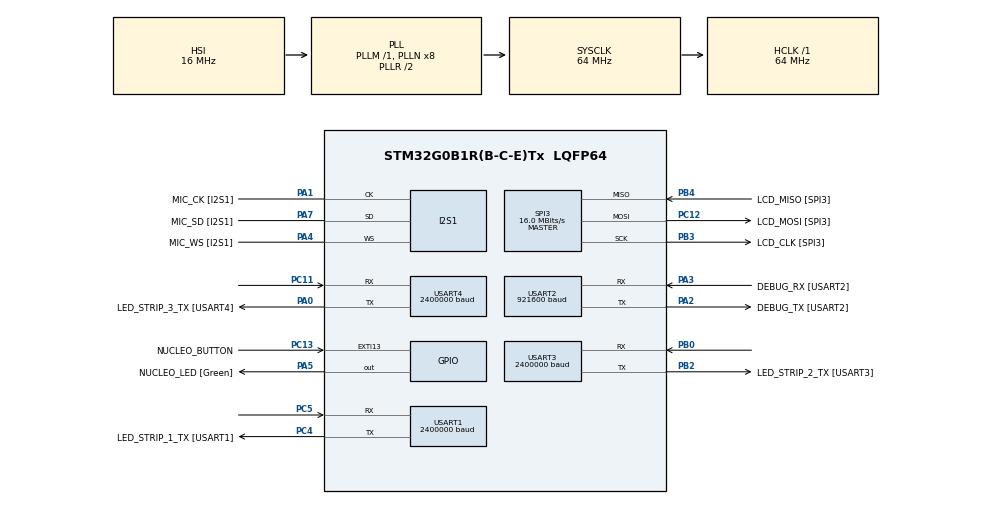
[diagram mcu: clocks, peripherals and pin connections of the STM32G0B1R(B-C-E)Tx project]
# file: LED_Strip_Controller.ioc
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Dma.Request0=USART1_TX
Dma.Request1=USART3_TX
Dma.Request2=USART4_TX
Dma.USART1_TX.0.Direction=DMA_MEMORY_TO_PERIPH
Dma.USART1_TX.0.EventEnable=DISABLE
Dma.USART1_TX.0.Instance=DMA1_Channel1
Dma.USART1_TX.0.MemDataAlignment=DMA_MDATAALIGN_BYTE
Dma.USART1_TX.0.MemInc=DMA_MINC_ENABLE
Dma.USART1_TX.0.Mode=DMA_NORMAL
Dma.USART1_TX.0.PeriphDataAlignment=DMA_PDATAALIGN_BYTE
Dma.USART1_TX.0.PeriphInc=DMA_PINC_DISABLE
Dma.USART1_TX.0.Polarity=HAL_DMAMUX_REQ_GEN_RISING
Dma.USART1_TX.0.Priority=DMA_PRIORITY_LOW
Dma.USART1_TX.0.RequestNumber=1
Dma.USART1_TX.0.SignalID=NONE
Dma.USART1_TX.0.SyncEnable=DISABLE
Dma.USART1_TX.0.SyncPolarity=HAL_DMAMUX_SYNC_NO_EVENT
Dma.USART1_TX.0.SyncRequestNumber=1
Dma.USART1_TX.0.SyncSignalID=NONE
Dma.USART3_TX.1.Direction=DMA_MEMORY_TO_PERIPH
Dma.USART3_TX.1.EventEnable=DISABLE
Dma.USART3_TX.1.Instance=DMA1_Channel2
Dma.USART3_TX.1.MemDataAlignment=DMA_MDATAALIGN_BYTE
Dma.USART3_TX.1.MemInc=DMA_MINC_ENABLE
Dma.USART3_TX.1.Mode=DMA_NORMAL
Dma.USART3_TX.1.PeriphDataAlignment=DMA_PDATAALIGN_BYTE
Dma.USART3_TX.1.PeriphInc=DMA_PINC_DISABLE
Dma.USART3_TX.1.Polarity=HAL_DMAMUX_REQ_GEN_RISING
Dma.USART3_TX.1.Priority=DMA_PRIORITY_LOW
Dma.USART3_TX.1.RequestNumber=1
Dma.USART3_TX.1.SignalID=NONE
Dma.USART3_TX.1.SyncEnable=DISABLE
Dma.USART3_TX.1.SyncPolarity=HAL_DMAMUX_SYNC_NO_EVENT
Dma.USART3_TX.1.SyncRequestNumber=1
Dma.USART3_TX.1.SyncSignalID=NONE
Dma.USART4_TX.2.Direction=DMA_MEMORY_TO_PERIPH
Dma.USART4_TX.2.EventEnable=DISABLE
Dma.USART4_TX.2.Instance=DMA1_Channel3
Dma.USART4_TX.2.MemDataAlignment=DMA_MDATAALIGN_BYTE
Dma.USART4_TX.2.MemInc=DMA_MINC_ENABLE
Dma.USART4_TX.2.Mode=DMA_NORMAL
Dma.USART4_TX.2.PeriphDataAlignment=DMA_PDATAALIGN_BYTE
Dma.USART4_TX.2.PeriphInc=DMA_PINC_DISABLE
Dma.USART4_TX.2.Polarity=HAL_DMAMUX_REQ_GEN_RISING
Dma.USART4_TX.2.Priority=DMA_PRIORITY_LOW
Dma.USART4_TX.2.RequestNumber=1
Dma.USART4_TX.2.SignalID=NONE
Dma.USART4_TX.2.SyncEnable=DISABLE
Dma.USART4_TX.2.SyncPolarity=HAL_DMAMUX_SYNC_NO_EVENT
Dma.USART4_TX.2.SyncRequestNumber=1
Dma.USART4_TX.2.SyncSignalID=NONE
I2S1.ErrorAudioFreq=0.0 %
I2S1.FullDuplexMode=I2S_FULLDUPLEXMODE_DISABLE
I2S1.Instance=SPI$Index
I2S1.RealAudioFreq=8.0 KHz
I2S1.VirtualMode=I2S_MODE_MASTER
Mcu.Family=STM32G0
Mcu.Name=STM32G0B1R(B-C-E)Tx
Mcu.Package=LQFP64
NVIC.DMA1_Channel1_IRQn=true\:1\:0\:true\:false\:true\:false\:true\:true
NVIC.DMA1_Channel2_3_IRQn=true\:1\:0\:true\:false\:true\:false\:true\:true
NVIC.USART1_IRQn=true\:0\:0\:false\:false\:true\:true\:true\:true
NVIC.USART3_4_5_6_LPUART1_IRQn=true\:0\:0\:false\:false\:true\:true\:true\:true
PA0.GPIO_Label=LED_STRIP_3_TX [USART4]
PA0.Mode=Asynchronous
PA0.Signal=USART4_TX
PA1.GPIO_Label=MIC_CK [I2S1]
PA1.Mode=Half_Duplex_Master
PA1.Signal=I2S1_CK
PA13.GPIO_Label=SWDATA [STLink]
PA13.Mode=Serial_Wire
PA13.Signal=SYS_SWDIO
PA14-BOOT0.GPIO_Label=SWCLK [STLink]
PA14-BOOT0.Mode=Serial_Wire
PA14-BOOT0.Signal=SYS_SWCLK
PA2.GPIO_Label=DEBUG_TX [USART2]
PA2.Mode=Asynchronous
PA2.Signal=USART2_TX
PA3.GPIO_Label=DEBUG_RX [USART2]
PA3.Mode=Asynchronous
PA3.Signal=USART2_RX
PA4.GPIO_Label=MIC_WS [I2S1]
PA4.Mode=Half_Duplex_Master
PA4.Signal=I2S1_WS
PA5.GPIO_Label=NUCLEO_LED [Green]
PA5.GPIO_Speed=GPIO_SPEED_FREQ_HIGH
PA5.Signal=GPIO_Output
PA7.GPIO_Label=MIC_SD [I2S1]
PA7.Mode=Half_Duplex_Master
PA7.Signal=I2S1_SD
PB0.Mode=Asynchronous
PB0.Signal=USART3_RX
PB2.GPIO_Label=LED_STRIP_2_TX [USART3]
PB2.Mode=Asynchronous
PB2.Signal=USART3_TX
PB3.GPIO_Label=LCD_CLK [SPI3]
PB3.Mode=Full_Duplex_Master
PB3.Signal=SPI3_SCK
PB4.GPIO_Label=LCD_MISO [SPI3]
PB4.Mode=Full_Duplex_Master
PB4.Signal=SPI3_MISO
PC11.Mode=Asynchronous
PC11.Signal=USART4_RX
PC12.GPIO_Label=LCD_MOSI [SPI3]
PC12.Mode=Full_Duplex_Master
PC12.Signal=SPI3_MOSI
PC13.GPIO_Label=NUCLEO_BUTTON
PC13.Signal=GPXTI13
PC14-OSC32_IN\ (PC14).Mode=LSE-External-Oscillator
PC14-OSC32_IN\ (PC14).Signal=RCC_OSC32_IN
PC15-OSC32_OUT\ (PC15).Mode=LSE-External-Oscillator
PC15-OSC32_OUT\ (PC15).Signal=RCC_OSC32_OUT
PC4.GPIO_Label=LED_STRIP_1_TX [USART1]
PC4.Mode=Asynchronous
PC4.Signal=USART1_TX
PC5.Mode=Asynchronous
PC5.Signal=USART1_RX
PF0-OSC_IN\ (PF0).GPIO_Label=MCO[Reserved]
PF0-OSC_IN\ (PF0).Mode=HSE-External-Clock-Source
PF0-OSC_IN\ (PF0).Signal=RCC_OSC_IN
ProjectManager.HeapSize=0x4000
ProjectManager.StackSize=0x1000
ProjectManager.TargetToolchain=STM32CubeIDE
RCC.ADCFreq_Value=64000000
RCC.AHBFreq_Value=64000000
RCC.CortexFreq_Value=64000000
RCC.EXTERNAL_CLOCK_VALUE=12288000
RCC.HCLKFreq_Value=64000000
RCC.HSE_VALUE=8000000
RCC.HSI48_VALUE=48000000
RCC.HSI_VALUE=16000000
RCC.SYSCLKFreq_VALUE=64000000
RCC.SYSCLKSource=RCC_SYSCLKSOURCE_PLLCLK
RCC.USBFreq_Value=48000000
RCC.VCOOutputFreq_Value=128000000
RTC.Format=RTC_FORMAT_BIN
SPI3.BaudRatePrescaler=SPI_BAUDRATEPRESCALER_4
SPI3.CLKPolarity=SPI_POLARITY_HIGH
SPI3.CalculateBaudRate=16.0 MBits/s
SPI3.DataSize=SPI_DATASIZE_8BIT
SPI3.Direction=SPI_DIRECTION_2LINES
SPI3.Mode=SPI_MODE_MASTER
SPI3.VirtualType=VM_MASTER
TIM6.Period=1000
TIM6.Prescaler=63
TIM7.Prescaler=63
USART1.BaudRate=2400000
USART1.FIFOMode=FIFOMODE_ENABLE
USART1.Mode=MODE_TX
USART1.OneBitSampling=UART_ONE_BIT_SAMPLE_ENABLE
USART1.OverSampling=UART_OVERSAMPLING_8
USART1.RXFIFOThreshold=RXFIFO_THRESHOLD_HALFFULL
USART1.TXFIFOThreshold=TXFIFO_THRESHOLD_HALFFULL
USART1.TxPinLevelInvertParam=ADVFEATURE_TXINV_ENABLE
USART1.VirtualMode-Asynchronous=VM_ASYNC
USART1.WordLength=WORDLENGTH_7B
USART2.BaudRate=921600
USART2.Mode=MODE_TX_RX
USART2.RXFIFOThreshold=RXFIFO_THRESHOLD_HALFFULL
USART2.TXFIFOThreshold=TXFIFO_THRESHOLD_HALFFULL
USART2.TxPinLevelInvertParam=ADVFEATURE_TXINV_DISABLE
USART2.VirtualMode-Asynchronous=VM_ASYNC
USART3.BaudRate=2400000
USART3.FIFOMode=FIFOMODE_ENABLE
USART3.Mode=MODE_TX
USART3.OneBitSampling=UART_ONE_BIT_SAMPLE_ENABLE
USART3.OverSampling=UART_OVERSAMPLING_8
USART3.RXFIFOThreshold=RXFIFO_THRESHOLD_HALFFULL
USART3.TXFIFOThreshold=TXFIFO_THRESHOLD_HALFFULL
USART3.TxPinLevelInvertParam=ADVFEATURE_TXINV_ENABLE
USART3.VirtualMode-Asynchronous=VM_ASYNC
USART3.WordLength=WORDLENGTH_7B
USART4.BaudRate=2400000
USART4.Mode=MODE_TX
USART4.OneBitSampling=UART_ONE_BIT_SAMPLE_ENABLE
USART4.OverSampling=UART_OVERSAMPLING_8
USART4.TxPinLevelInvertParam=ADVFEATURE_TXINV_ENABLE
USART4.VirtualMode-Asynchronous=VM_ASYNC
USART4.WordLength=WORDLENGTH_7B
VP_RTC_VS_RTC_Activate.Mode=RTC_Enabled
VP_RTC_VS_RTC_Calendar.Mode=RTC_Calendar
VP_SYS_VS_DBSignals.Mode=DisableDeadBatterySignals
VP_TIM14_VS_ClockSourceINT.Mode=Enable_Timer
VP_TIM6_VS_ClockSourceINT.Mode=Enable_Timer
VP_TIM7_VS_ClockSourceINT.Mode=Enable_Timer
board=NUCLEO-G0B1RE

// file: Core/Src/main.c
/* USER CODE BEGIN Header */
/**
  ******************************************************************************
  * @file           : main.c
  * @brief          : Main program body
  ******************************************************************************
  * @attention
  *
  * Copyright (c) 2026 STMicroelectronics.
  * All rights reserved.
  *
  * This software is licensed under terms that can be found in the LICENSE file
  * in the root directory of this software component.
  * If no LICENSE file comes with this software, it is provided AS-IS.
  *
  ******************************************************************************
  */
/* USER CODE END Header */
#include "main.h"
#include "dma.h"
#include "i2s.h"
#include "rtc.h"
#include "spi.h"
#include "tim.h"
#include "usart.h"
#include "gpio.h"

/* USER CODE BEGIN Includes */
#include <stdio.h>
/* USER CODE END Includes */

void SystemClock_Config(void);

int main(void)
{

  /* MCU Configuration--------------------------------------------------------*/

  /* Reset of all peripherals, Initializes the Flash interface and the Systick. */
  HAL_Init();

  /* Configure the system clock */
  SystemClock_Config();

  /* Initialize all configured peripherals */
  MX_GPIO_Init();
  MX_DMA_Init();
  MX_USART1_UART_Init();
  MX_USART2_UART_Init();
  MX_USART3_UART_Init();
  MX_USART4_UART_Init();
  MX_TIM6_Init();
  MX_TIM7_Init();
  MX_RTC_Init();
  MX_I2S1_Init();
  MX_SPI3_Init();
  MX_TIM14_Init();
  /* USER CODE BEGIN 2 */

  // Disable I/O buffering for STDxxx streams, so that I/O data is
  // sent/received immediately; no internal wait-for-EOL buffering
  setvbuf(stdout, NULL, _IONBF, 0);
  setvbuf(stdin, NULL, _IONBF, 0);
  setvbuf(stderr, NULL, _IONBF, 0);

  /* USER CODE END 2 */

  /* Infinite loop */

    /* USER CODE BEGIN 3 */
  extern void v_app_main(void);
  v_app_main();
  /* USER CODE END 3 */
}

void SystemClock_Config(void)
{
  RCC_OscInitTypeDef RCC_OscInitStruct = {0};
  RCC_ClkInitTypeDef RCC_ClkInitStruct = {0};

  /** Configure the main internal regulator output voltage
  */
  HAL_PWREx_ControlVoltageScaling(PWR_REGULATOR_VOLTAGE_SCALE1);

  /** Initializes the RCC Oscillators according to the specified parameters
  * in the RCC_OscInitTypeDef structure.
  */
  RCC_OscInitStruct.OscillatorType = RCC_OSCILLATORTYPE_HSI|RCC_OSCILLATORTYPE_LSI;
  RCC_OscInitStruct.HSIState = RCC_HSI_ON;
  RCC_OscInitStruct.HSIDiv = RCC_HSI_DIV1;
  RCC_OscInitStruct.HSICalibrationValue = RCC_HSICALIBRATION_DEFAULT;
  RCC_OscInitStruct.LSIState = RCC_LSI_ON;
  RCC_OscInitStruct.PLL.PLLState = RCC_PLL_ON;
  RCC_OscInitStruct.PLL.PLLSource = RCC_PLLSOURCE_HSI;
  RCC_OscInitStruct.PLL.PLLM = RCC_PLLM_DIV1;
  RCC_OscInitStruct.PLL.PLLN = 8;
  RCC_OscInitStruct.PLL.PLLP = RCC_PLLP_DIV2;
  RCC_OscInitStruct.PLL.PLLQ = RCC_PLLQ_DIV2;
  RCC_OscInitStruct.PLL.PLLR = RCC_PLLR_DIV2;
  if (HAL_RCC_OscConfig(&RCC_OscInitStruct) != HAL_OK)
  {
    Error_Handler();
  }

  /** Initializes the CPU, AHB and APB buses clocks
  */
  RCC_ClkInitStruct.ClockType = RCC_CLOCKTYPE_HCLK|RCC_CLOCKTYPE_SYSCLK
                              |RCC_CLOCKTYPE_PCLK1;
  RCC_ClkInitStruct.SYSCLKSource = RCC_SYSCLKSOURCE_PLLCLK;
  RCC_ClkInitStruct.AHBCLKDivider = RCC_SYSCLK_DIV1;
  RCC_ClkInitStruct.APB1CLKDivider = RCC_HCLK_DIV1;

  if (HAL_RCC_ClockConfig(&RCC_ClkInitStruct, FLASH_LATENCY_2) != HAL_OK)
  {
    Error_Handler();
  }
}

void Error_Handler(void)
{
  __disable_irq();
  while (1)
  {
  }
}
